# netx90_app register map
File version: 1.0
CPU: CM4 r0p1, little endian, MPU, FPU, 4 interrupt priority bits, 78 interrupts
Registers are 32-bit, read-write, reset 0x0 unless marked. A register's access mark holds for its fields unless they carry their own. Offsets are from the block's base; [hi:lo] are bit positions; 'fields as' and 'values as' point back to an identical list.

## wdg_app
Base 0xFF801700
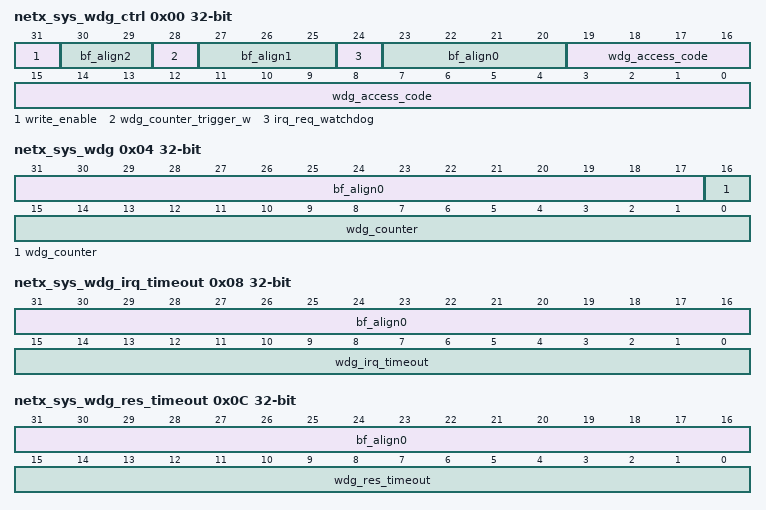
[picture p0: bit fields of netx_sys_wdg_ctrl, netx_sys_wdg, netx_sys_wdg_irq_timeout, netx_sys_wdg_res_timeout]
0x00 netx_sys_wdg_ctrl (reset mask 0x910FFFFF) — netX System Watchdog Trigger Register. The watchdog access code is generated by a pseudo random generator. It must be written correctly for a valid write access to this register (not only for triggering e.g. also for IRQ clearing). Note: WDGACT signal is available as MMIO function..
  [31] write_enable — Write enable bit for timeout register: As long as this bit is not set all write accesses to the timeout register are ignored.
  [30:29] bf_align2 — bitField alignment value for aeabi compatibility
  [28] wdg_counter_trigger_w — Watchdog trigger bit: Bit must be set to trigger the watchdog counter. When read, this bit is always '0'
  [27:25] bf_align1 — bitField alignment value for aeabi compatibility
  [24] irq_req_watchdog — IRQ request of watchdog, writing 1 deletes IRQ
  [23:20] bf_align0 — bitField alignment value for aeabi compatibility
  [19:0] wdg_access_code — Watchdog trigger and control register access code. A read access gives the next 16 bit code for writing the 'netx_sys_wdg_ctrl' register. A write access with correct access code will trigger the watchdog counter.
0x04 netx_sys_wdg ro (reset mask 0x1FFFF) — netX System Watchdog Register The counter value is decremented each 10000 system clock cycles.
  [31:17] bf_align0 — bitField alignment value for aeabi compatibility
  [16:0] wdg_counter — Actual watchdog counter value
0x08 netx_sys_wdg_irq_timeout (reset mask 0xFFFF) — netX System Wachtdog Interrupt Timout Register
  [31:16] bf_align0 — bitField alignment value for aeabi compatibility
  [15:0] wdg_irq_timeout — Watchdog interrupt timeout The total netx_sys_irq timeout for a netX clock of 100MHz is: wdg_irq_timeout * 100us Note: The watchdog can be stopped by programming a 0.
0x0C netx_sys_wdg_res_timeout (reset mask 0xFFFF) — netX System Watchdog Reset Timeout Register
  [31:16] bf_align0 — bitField alignment value for aeabi compatibility
  [15:0] wdg_res_timeout — Watchdog reset request timeout The total reset timeout for a netX clock of 100MHz is: (wdg_irq_timeout + wdg_res_timeout) * 100us Note: The watchdog can be stopped by programming a 0.
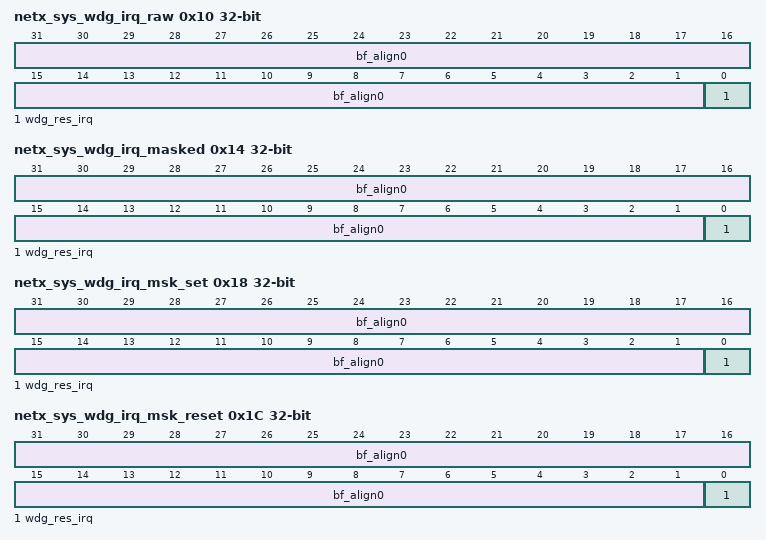
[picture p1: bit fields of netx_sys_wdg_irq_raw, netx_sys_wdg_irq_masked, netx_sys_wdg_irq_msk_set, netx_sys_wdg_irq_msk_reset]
0x10 netx_sys_wdg_irq_raw (reset mask 0x1) — netX System Wachtdog IRQ raw register: Read access shows status of unmasked IRQs. IRQs are set automatically and reset by writing to this register: Write access with '1' resets the appropriate IRQ. Write access with '0' does not influence this bit.
  [31:1] bf_align0 — bitField alignment value for aeabi compatibility
  [0] wdg_res_irq — Watchdog reset request timeout interrupt
0x14 netx_sys_wdg_irq_masked ro (reset mask 0x1) — netX System Wachtdog Masked IRQ register: Read access shows status of masked IRQs.
  fields as netx_sys_wdg_irq_raw
0x18 netx_sys_wdg_irq_msk_set (reset mask 0x1) — netX System Wachtdog interrupt mask enable: The IRQ mask enables interrupt requests for corresponding interrupt sources. As its bits might be changed by different software tasks, the IRQ mask register is not writable directly, but by set and reset masks: Write access with '1' sets interrupt mask bit (enables interrupt request for corresponding interrupt source). Write access with '0' does not influence this bit. Read access shows actual interrupt mask. Attention: Before activating interrupt mask, delete old pending interrupts by writing the same value to irq_raw.
  fields as netx_sys_wdg_irq_raw
0x1C netx_sys_wdg_irq_msk_reset (reset mask 0x1) — netX System Wachtdog interrupt mask disable: This is the corresponding reset mask to disable interrupt requests for corresponding interrupt sources: Write access with '1' resets interrupt mask bit (disables interrupt request for corresponding interrupt source). Write access with '0' does not influence this bit. Read access shows actual interrupt mask.
  fields as netx_sys_wdg_irq_raw
